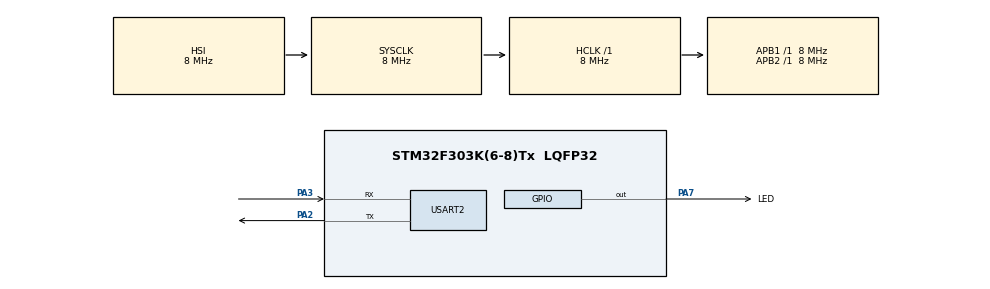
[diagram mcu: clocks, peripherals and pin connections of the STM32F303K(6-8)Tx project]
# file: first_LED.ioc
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Mcu.Family=STM32F3
Mcu.Name=STM32F303K(6-8)Tx
Mcu.Package=LQFP32
NVIC.PriorityGroup=NVIC_PRIORITYGROUP_4
PA13.GPIO_Label=SWDIO
PA13.Mode=Serial_Wire
PA13.Signal=SYS_JTMS-SWDIO
PA14.GPIO_Label=SWCLK
PA14.Mode=Serial_Wire
PA14.Signal=SYS_JTCK-SWCLK
PA2.Mode=Asynchronous
PA2.Signal=USART2_TX
PA3.Mode=Asynchronous
PA3.Signal=USART2_RX
PA7.GPIO_Label=LED
PA7.Signal=GPIO_Output
PF0\ /\ OSC_IN.GPIO_Label=MCO
PF0\ /\ OSC_IN.Mode=HSE-External-Clock-Source
PF0\ /\ OSC_IN.Signal=RCC_OSC_IN
ProjectManager.HeapSize=0x200
ProjectManager.StackSize=0x400
ProjectManager.TargetToolchain=STM32CubeIDE
RCC.AHBFreq_Value=8000000
RCC.APB1Freq_Value=8000000
RCC.APB2Freq_Value=8000000
RCC.CortexFreq_Value=8000000
RCC.HSE_VALUE=8000000
RCC.HSI_VALUE=8000000
RCC.SYSCLKFreq_VALUE=8000000
USART2.VirtualMode-Asynchronous=VM_ASYNC
board=NUCLEO-F303K8

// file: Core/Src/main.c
/* USER CODE BEGIN Header */
/**
 ******************************************************************************
 * @file           : main.c
 * @brief          : Main program body
 ******************************************************************************
 * @attention
 *
 * <h2><center>&copy; Copyright (c) 2019 STMicroelectronics.
 * All rights reserved.</center></h2>
 *
 * This software component is licensed by ST under BSD 3-Clause license,
 * the "License"; You may not use this file except in compliance with the
 * License. You may obtain a copy of the License at:
 *                        opensource.org/licenses/BSD-3-Clause
 *
 ******************************************************************************
 */
/* USER CODE END Header */

#include "main.h"

UART_HandleTypeDef huart2;

void SystemClock_Config(void);
static void MX_GPIO_Init(void);
static void MX_USART2_UART_Init(void);
/* USER CODE BEGIN PFP */
static void Pulse(int Tof);
static void inv_Pulse(int Tof);
static void LeaderPulse(void);
static void inv_LeaderPulse(void);
static void Pulse_zero_or_one(int ToF);
static void inv_Pulse_zero_or_one(int ToF);
/* USER CODE END PFP */

/* USER CODE BEGIN 0 */
//Power ON
int remote_control_code_array[6] = { 0x55, 0x5A, 0xF1, 0x48, 0x68, 0x8B };
//service mode
//int remote_control_code_array[6] = { 0x55, 0x5A, 0xF1, 0x0C, 0xAF, 0x80 };

int T = 17;
/* USER CODE END 0 */

int main(void) {

	/* MCU Configuration--------------------------------------------------------*/

	/* Reset of all peripherals, Initializes the Flash interface and the Systick. */
	HAL_Init();

	/* Configure the system clock */
	SystemClock_Config();

	/* Initialize all configured peripherals */
	MX_GPIO_Init();
	MX_USART2_UART_Init();

	/* Infinite loop */
	/* USER CODE BEGIN WHILE */
	while (1) {
		inv_LeaderPulse();
		for (int k = 0; k < 1; k++) {
			for (int i = 0; i < (sizeof(remote_control_code_array)) / 4; i++) {
				for (int j = 0; j < 8; j++) {
					inv_Pulse(
							((remote_control_code_array[i] >> (7 - j)) & 0b1));
				}
			}
			inv_Pulse(1);
			HAL_Delay(6);
			/* USER CODE END WHILE */
			/* USER CODE BEGIN 3 */
		}
		/* USER CODE END WHILE */
		/* USER CODE BEGIN 3 */
		HAL_Delay(5000);
	}
	/* USER CODE END 3 */
}

void SystemClock_Config(void) {
	RCC_OscInitTypeDef RCC_OscInitStruct = { 0 };
	RCC_ClkInitTypeDef RCC_ClkInitStruct = { 0 };

	/** Initializes the CPU, AHB and APB busses clocks
	 */
	RCC_OscInitStruct.OscillatorType = RCC_OSCILLATORTYPE_HSI;
	RCC_OscInitStruct.HSIState = RCC_HSI_ON;
	RCC_OscInitStruct.HSICalibrationValue = RCC_HSICALIBRATION_DEFAULT;
	RCC_OscInitStruct.PLL.PLLState = RCC_PLL_NONE;
	if (HAL_RCC_OscConfig(&RCC_OscInitStruct) != HAL_OK) {
		Error_Handler();
	}
	/** Initializes the CPU, AHB and APB busses clocks
	 */
	RCC_ClkInitStruct.ClockType = RCC_CLOCKTYPE_HCLK | RCC_CLOCKTYPE_SYSCLK
			| RCC_CLOCKTYPE_PCLK1 | RCC_CLOCKTYPE_PCLK2;
	RCC_ClkInitStruct.SYSCLKSource = RCC_SYSCLKSOURCE_HSI;
	RCC_ClkInitStruct.AHBCLKDivider = RCC_SYSCLK_DIV1;
	RCC_ClkInitStruct.APB1CLKDivider = RCC_HCLK_DIV1;
	RCC_ClkInitStruct.APB2CLKDivider = RCC_HCLK_DIV1;

	if (HAL_RCC_ClockConfig(&RCC_ClkInitStruct, FLASH_LATENCY_0) != HAL_OK) {
		Error_Handler();
	}
}

static void MX_USART2_UART_Init(void) {

	huart2.Instance = USART2;
	huart2.Init.BaudRate = 38400;
	huart2.Init.WordLength = UART_WORDLENGTH_8B;
	huart2.Init.StopBits = UART_STOPBITS_1;
	huart2.Init.Parity = UART_PARITY_NONE;
	huart2.Init.Mode = UART_MODE_TX_RX;
	huart2.Init.HwFlowCtl = UART_HWCONTROL_NONE;
	huart2.Init.OverSampling = UART_OVERSAMPLING_16;
	huart2.Init.OneBitSampling = UART_ONE_BIT_SAMPLE_DISABLE;
	huart2.AdvancedInit.AdvFeatureInit = UART_ADVFEATURE_NO_INIT;
	if (HAL_UART_Init(&huart2) != HAL_OK) {
		Error_Handler();
	}

}

static void MX_GPIO_Init(void) {
	GPIO_InitTypeDef GPIO_InitStruct = { 0 };

	/* GPIO Ports Clock Enable */
	__HAL_RCC_GPIOF_CLK_ENABLE();
	__HAL_RCC_GPIOA_CLK_ENABLE();

	/*Configure GPIO pin Output Level */
	HAL_GPIO_WritePin(LED_GPIO_Port, LED_Pin, GPIO_PIN_RESET);

	/*Configure GPIO pin : LED_Pin */
	GPIO_InitStruct.Pin = LED_Pin;
	GPIO_InitStruct.Mode = GPIO_MODE_OUTPUT_PP;
	GPIO_InitStruct.Pull = GPIO_NOPULL;
	GPIO_InitStruct.Speed = GPIO_SPEED_FREQ_LOW;
	HAL_GPIO_Init(LED_GPIO_Port, &GPIO_InitStruct);

}

/* USER CODE BEGIN 4 */

static void LeaderPulse(void) {
	for (int i = 0; i < (T * 8) - (T - 1); i++) {
		Pulse_zero_or_one(1);
	}
	for (int i = 0; i < (T * 4) - (T - 7); i++) {
		Pulse_zero_or_one(0);
	}
}

static void inv_LeaderPulse(void) {
	for (int i = 0; i < (T * 8) - (T - 1); i++) {
		inv_Pulse_zero_or_one(1);
	}
	for (int i = 0; i < (T * 4) - (T - 7); i++) {
		inv_Pulse_zero_or_one(0);
	}
}

static void Pulse(int ToF) {
	for (int i = 0; i < T * 1; i++) {
		Pulse_zero_or_one(1);
	}
	if (ToF == 0) {
		for (int i = 0; i < T * 1; i++) {
			Pulse_zero_or_one(0);
		}
	} else {
		for (int i = 0; i < T * 3; i++) {
			Pulse_zero_or_one(0);
		}
	}
}

static void inv_Pulse(int ToF) {
	for (int i = 0; i < T * 1; i++) {
		inv_Pulse_zero_or_one(1);
	}
	if (ToF == 0) {
		for (int i = 0; i < T * 1; i++) {
			inv_Pulse_zero_or_one(0);
		}
	} else {
		for (int i = 0; i < T * 3; i++) {
			inv_Pulse_zero_or_one(0);
		}
	}
}

static void Pulse_zero_or_one(int ToF) {
	if (ToF == 0) {
		HAL_GPIO_WritePin(LED_GPIO_Port, LED_Pin, GPIO_PIN_RESET);
		HAL_GPIO_WritePin(LED_GPIO_Port, LED_Pin, GPIO_PIN_RESET);
		HAL_GPIO_WritePin(LED_GPIO_Port, LED_Pin, GPIO_PIN_RESET);
		HAL_GPIO_WritePin(LED_GPIO_Port, LED_Pin, GPIO_PIN_RESET);
		HAL_GPIO_WritePin(LED_GPIO_Port, LED_Pin, GPIO_PIN_RESET);
		HAL_GPIO_WritePin(LED_GPIO_Port, LED_Pin, GPIO_PIN_RESET);
	} else {
		HAL_GPIO_WritePin(LED_GPIO_Port, LED_Pin, GPIO_PIN_SET);
		HAL_GPIO_WritePin(LED_GPIO_Port, LED_Pin, GPIO_PIN_SET);
		HAL_GPIO_WritePin(LED_GPIO_Port, LED_Pin, GPIO_PIN_RESET);
		HAL_GPIO_WritePin(LED_GPIO_Port, LED_Pin, GPIO_PIN_RESET);
		HAL_GPIO_WritePin(LED_GPIO_Port, LED_Pin, GPIO_PIN_RESET);
		HAL_GPIO_WritePin(LED_GPIO_Port, LED_Pin, GPIO_PIN_RESET);
	}
}

static void inv_Pulse_zero_or_one(int ToF) {
	if (ToF == 0) {
		HAL_GPIO_WritePin(LED_GPIO_Port, LED_Pin, GPIO_PIN_SET);
		HAL_GPIO_WritePin(LED_GPIO_Port, LED_Pin, GPIO_PIN_SET);
		HAL_GPIO_WritePin(LED_GPIO_Port, LED_Pin, GPIO_PIN_SET);
		HAL_GPIO_WritePin(LED_GPIO_Port, LED_Pin, GPIO_PIN_SET);
		HAL_GPIO_WritePin(LED_GPIO_Port, LED_Pin, GPIO_PIN_SET);
		HAL_GPIO_WritePin(LED_GPIO_Port, LED_Pin, GPIO_PIN_SET);
	} else {
		HAL_GPIO_WritePin(LED_GPIO_Port, LED_Pin, GPIO_PIN_RESET);
		HAL_GPIO_WritePin(LED_GPIO_Port, LED_Pin, GPIO_PIN_RESET);
		HAL_GPIO_WritePin(LED_GPIO_Port, LED_Pin, GPIO_PIN_SET);
		HAL_GPIO_WritePin(LED_GPIO_Port, LED_Pin, GPIO_PIN_SET);
		HAL_GPIO_WritePin(LED_GPIO_Port, LED_Pin, GPIO_PIN_SET);
		HAL_GPIO_WritePin(LED_GPIO_Port, LED_Pin, GPIO_PIN_SET);
	}
}

/* USER CODE END 4 */

void Error_Handler(void) {
}

/************************ (C) COPYRIGHT STMicroelectronics *****END OF FILE****/
